# LPC865 register map
Vendor: nxp.com; File version: 1.0
CPU: CM0PLUS r0p0, little endian, no MPU, no FPU, VTOR, 2 interrupt priority bits
Registers are 32-bit, read-write, reset 0x0 unless marked. A register's access mark holds for its fields unless they carry their own. Offsets are from the block's base; [hi:lo] are bit positions; lines under a group give offsets from that group; {n}, {i} and the like mark numbered series; 'fields as' and 'values as' point back to an identical list.

## FTM0 — FTM
Base 0x50009000
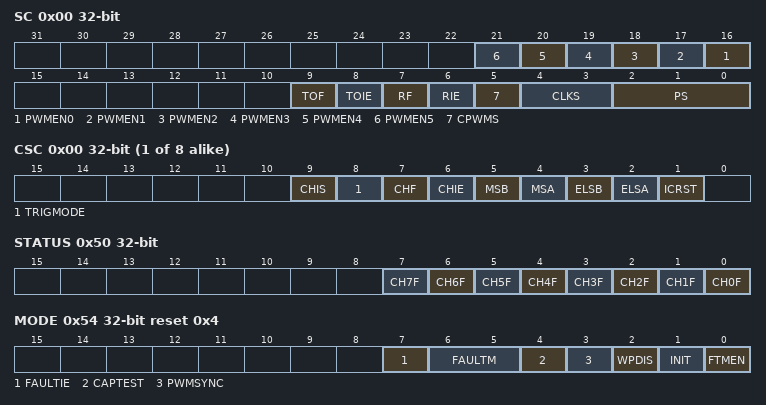
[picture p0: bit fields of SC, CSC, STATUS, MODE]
0x00 SC — Status And Control
  [n+16] PWMEN{n} (n=0..5) — Channel {n} PWM enable bit
    0=PWMEN_disabled (Channel output port is disabled.); 1=PWMEN_enabled (Channel output port is enabled.)
  [9] TOF — Timer Overflow Flag
    0=TOF_nooverflow (FTM counter has not overflowed.); 1=TOF_overflow (FTM counter has overflowed.)
  [8] TOIE — Timer Overflow Interrupt Enable
    0=TOIE_disabletof (Disable TOF interrupts. Use software polling.); 1=TOIE_enabletof (Enable TOF interrupts. An interrupt is generated when TOF equals one.)
  [7] RF — Reload Flag
    0=RF_no (A selected reload point did not happen.); 1=RF_yes (A selected reload point happened.)
  [6] RIE — Reload Point Interrupt Enable
    0=RIE_disabled (Reload point interrupt is disabled.); 1=RIE_enabled (Reload point interrupt is enabled.)
  [5] CPWMS — Center-Aligned PWM Select
    0=CPWMS_upcount (FTM counter operates in Up Counting mode.); 1=CPWMS_updowncount (FTM counter operates in Up-Down Counting mode.)
  [4:3] CLKS — Clock Source Selection
    0=CLKS_noclock (No clock selected. This in effect disables the FTM counter.); 1=CLKS_ftminputclock (FTM input clock); 2=CLKS_ffclk (Fixed frequency clock); 3=CLKS_extclk (External clock)
  [2:0] PS — Prescale Factor Selection
    0=PS_divideby1 (Divide by 1); 1=PS_divideby2 (Divide by 2); 2=PS_divideby4 (Divide by 4); 3=PS_divideby8 (Divide by 8); 4=PS_divideby16 (Divide by 16); 5=PS_divideby32 (Divide by 32); 6=PS_divideby64 (Divide by 64); 7=PS_divideby128 (Divide by 128)
0x04 CNT — Counter
  [15:0] COUNT — Counter Value
0x08 MOD — Modulo
  [15:0] MOD
{0xC+8i} CONTROLS[{i}] (i=0..7) group
  0x00 CSC — Channel (n) Status And Control
    [9] CHIS ro — Channel (n) Input State
      0=CHIS_zero (The channel (n) input is zero.); 1=CHIS_one (The channel (n) input is one.)
    [8] TRIGMODE — Trigger mode control
      0=TRIGMODE_normal (Channel outputs will generate the normal PWM outputs without generating a pulse.); 1=TRIGMODE_trigger (If a match in the channel occurs, a trigger generation on channel output will happen. The trigger pulse width has one FTM clock cycle.)
    [7] CHF — Channel (n) Flag
      0=CHF_event_no (No channel (n) event has occurred.); 1=CHF_event_yes (A channel (n) event has occurred.)
    [6] CHIE — Channel (n) Interrupt Enable
      0=CHIE_disable (Disable channel (n) interrupt. Use software polling.); 1=CHIE_enable (Enable channel (n) interrupt.)
    [5] MSB — Channel (n) Mode Select
    [4] MSA — Channel (n) Mode Select
    [3] ELSB — Channel (n) Edge or Level Select
    [2] ELSA — Channel (n) Edge or Level Select
    [1] ICRST — FTM counter reset by the selected input capture event.
      0=ICRST_notreset (FTM counter is not reset when the selected channel (n) input event is detected.); 1=ICRST_reset (FTM counter is reset when the selected channel (n) input event is detected.)
  0x04 CV — Channel (n) Value
    [15:0] VAL — Channel Value
0x4C CNTIN — Counter Initial Value
  [15:0] INIT
0x50 STATUS — Capture And Compare Status
  [all] fields
    0=CHF_event_no (No channel event has occurred.); 1=CHF_event_yes (A channel event has occurred.)
  [n] CH{n}F (n=0..7) — Channel {n} Flag
0x54 MODE reset 0x4 — Features Mode Selection
  [7] FAULTIE — Fault Interrupt Enable
    0=FAULTIE_disabled (Fault control interrupt is disabled.); 1=FAULTIE_enabled (Fault control interrupt is enabled.)
  [6:5] FAULTM — Fault Control Mode
    0=FAULTM_disabled (Fault control is disabled for all channels.); 1=FAULTM_enabled_even (Fault control is enabled for even channels only (channels 0, 2, 4, and 6), and the selected mode is the manual fault clearing.); 2=FAULTM_enabled_manual (Fault control is enabled for all channels, and the selected mode is the manual fault clearing.); 3=FAULTM_enabled_auto (Fault control is enabled for all channels, and the selected mode is the automatic fault clearing.)
  [4] CAPTEST — Capture Test Mode Enable
    0=CAPTEST_disabled (Capture test mode is disabled.); 1=CAPTEST_enabled (Capture test mode is enabled.)
  [3] PWMSYNC — PWM Synchronization Mode
    0=PWMSYNC_restrict_no (No restrictions. Software and hardware triggers can be used by MOD, CnV, OUTMASK, and FTM counter synchronization.); 1=PWMSYNC_restrict_yes (Software trigger can only be used by MOD and CnV synchronization, and hardware triggers can only be used by OUTMASK and FTM counter synchronization.)
  [2] WPDIS — Write Protection Disable
    0=WPDIS_enabled (Write protection is enabled.); 1=WPDIS_disabled (Write protection is disabled.)
  [1] INIT — Initialize The Channels Output
  [0] FTMEN — FTM Enable
    0=FTMEN_compatible_yes (TPM compatibility. Free running counter and synchronization compatible with TPM.); 1=FTMEN_compatible_no (Free running counter and synchronization are different from TPM behavior.)
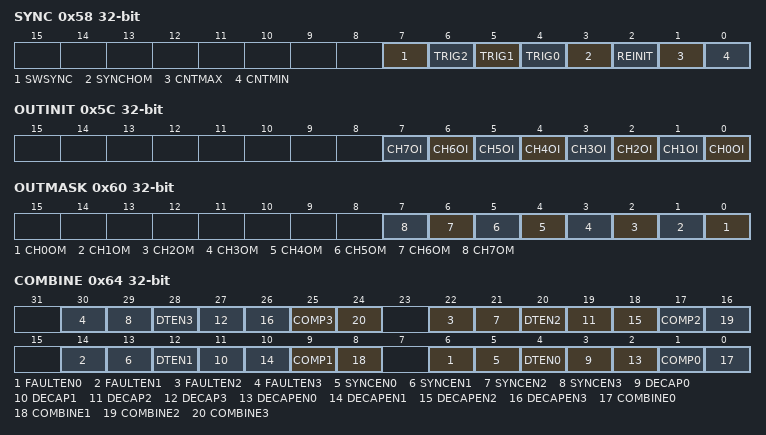
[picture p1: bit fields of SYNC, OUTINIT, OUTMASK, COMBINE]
0x58 SYNC — Synchronization
  [7] SWSYNC — PWM Synchronization Software Trigger
    0=SWSYNC_notselected (Software trigger is not selected.); 1=SWSYNC_selected (Software trigger is selected.)
  [6] TRIG2 — PWM Synchronization Hardware Trigger 2
    0=TRIG2_disabled (Trigger is disabled.); 1=TRIG2_enabled (Trigger is enabled.)
  [5] TRIG1 — PWM Synchronization Hardware Trigger 1
    0=TRIG1_disabled (Trigger is disabled.); 1=TRIG1_enabled (Trigger is enabled.)
  [4] TRIG0 — PWM Synchronization Hardware Trigger 0
    0=TRIG0_disabled (Trigger is disabled.); 1=TRIG0_enabled (Trigger is enabled.)
  [3] SYNCHOM — Output Mask Synchronization
    0=SYNCHOM_ftm (OUTMASK register is updated with the value of its buffer in all rising edges of the FTM input clock.); 1=SYNCHOM_pwm (OUTMASK register is updated with the value of its buffer only by the PWM synchronization.)
  [2] REINIT — FTM Counter Reinitialization by Synchronization
    0=REINIT_normal (FTM counter continues to count normally.); 1=REINIT_trigger (FTM counter is updated with its initial value when the selected trigger is detected.)
  [1] CNTMAX — Maximum Loading Point Enable
    0=CNTMAX_disabled (The maximum loading point is disabled.); 1=CNTMAX_enabled (The maximum loading point is enabled.)
  [0] CNTMIN — Minimum Loading Point Enable
    0=CNTMIN_disabled (The minimum loading point is disabled.); 1=CNTMIN_enabled (The minimum loading point is enabled.)
0x5C OUTINIT — Initial State For Channels Output
  [all] fields
    0=CHOI_zero (The initialization value is 0.); 1=CHOI_one (The initialization value is 1.)
  [n] CH{n}OI (n=0..7) — Channel {n} Output Initialization Value
0x60 OUTMASK — Output Mask
  [all] fields
    0=CHOM_normal (Channel output is not masked. It continues to operate normally.); 1=CHOM_inactive (Channel output is masked. It is forced to its inactive state.)
  [n] CH{n}OM (n=0..7) — Channel {n} Output Mask
0x64 COMBINE — Function For Linked Channels
  [8n+6] FAULTEN{n} (n=0..3) — Fault Control Enable For n = {2n}
    0=FAULTEN{n}_disabled (The fault control in this pair of channels is disabled.); 1=FAULTEN{n}_enabled (The fault control in this pair of channels is enabled.)
  [8n+5] SYNCEN{n} (n=0..3) — Synchronization Enable For n = {2n}
    0=SYNCEN{n}_disabled (The PWM synchronization in this pair of channels is disabled.); 1=SYNCEN{n}_enabled (The PWM synchronization in this pair of channels is enabled.)
  [8n+4] DTEN{n} (n=0..3) — Deadtime Enable For n = {2n}
    0=DTEN{n}_disabled (The deadtime insertion in this pair of channels is disabled.); 1=DTEN{n}_enabled (The deadtime insertion in this pair of channels is enabled.)
  [8n+3] DECAP{n} (n=0..3) — Dual Edge Capture Mode Captures For n = {2n}
    0=DECAP{n}_inactive (The dual edge captures are inactive.); 1=DECAP{n}_active (The dual edge captures are active.)
  [8n+2] DECAPEN{n} (n=0..3) — Dual Edge Capture Mode Enable For n = {2n}
  [25] COMP3 — Complement Of Channel (n) for n = 6
    0=COMP3_same_modcomb (If the channels (n) and (n+1) are in Combine Mode or Modified Combine PWM Mode, the channel (n+1) output is the same as the channel (n) output. If the channel (n+1) is in Output Compare Mode, EPWM or CPWM, the channel (n+1) output is independent from channel (n) output.); 1=COMP3_complement (The channel (n+1) output is the complement of the channel (n) output.)
  [8n] COMBINE{n} (n=0..3) — Combine Channels For n = {2n}
  [17] COMP2 — Complement Of Channel (n) For n = 4
    0=COMP2_same_modcomb (If the channels (n) and (n+1) are in Combine Mode or Modified Combine PWM Mode, the channel (n+1) output is the same as the channel (n) output. If the channel (n+1) is in Output Compare Mode, EPWM or CPWM, the channel (n+1) output is independent from channel (n) output.); 1=COMP2_complement (The channel (n+1) output is the complement of the channel (n) output.)
  [9] COMP1 — Complement Of Channel (n) For n = 2
    0=COMP1_modcomb (If the channels (n) and (n+1) are in Combine Mode or Modified Combine PWM Mode, the channel (n+1) output is the same as the channel (n) output. If the channel (n+1) is in Output Compare Mode, EPWM or CPWM, the channel (n+1) output is independent from channel (n) output.); 1=COMP1_complement (The channel (n+1) output is the complement of the channel (n) output.)
  [1] COMP0 — Complement Of Channel (n) For n = 0
    0=COMP0_same_modcomb (If the channels (n) and (n+1) are in Combine Mode or Modified Combine PWM Mode, the channel (n+1) output is the same as the channel (n) output. If the channel (n+1) is in Output Compare Mode, EPWM or CPWM, the channel (n+1) output is independent from channel (n) output.); 1=COMP0_complement (The channel (n+1) output is the complement of the channel (n) output.)
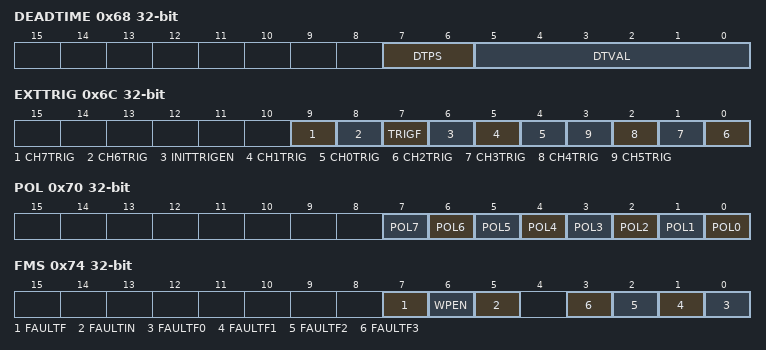
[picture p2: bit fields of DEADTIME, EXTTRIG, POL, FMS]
0x68 DEADTIME — Deadtime Configuration
  [7:6] DTPS — Deadtime Prescaler Value
    0b0x=DTPS_divideby1 (Divide the FTM input clock by 1.); 2=DTPS_divideby4 (Divide the FTM input clock by 4.); 3=DTPS_divideby16 (Divide the FTM input clock by 16.)
  [5:0] DTVAL — Deadtime Value
0x6C EXTTRIG — FTM External Trigger
  [9] CH7TRIG — Channel 7 External Trigger Enable
    0=CH7TRIG_disabled (The generation of this external trigger is disabled.); 1=CH7TRIG_enabled (The generation of this external trigger is enabled.)
  [8] CH6TRIG — Channel 6 External Trigger Enable
    0=CH6TRIG_disabled (The generation of this external trigger is disabled.); 1=CH6TRIG_enabled (The generation of this external trigger is enabled.)
  [7] TRIGF — Channel Trigger Flag
    0=TRIGF_no (No channel trigger was generated.); 1=TRIGF_yes (A channel trigger was generated.)
  [6] INITTRIGEN — Initialization Trigger Enable
    0=INITTRIGEN_disabled (The generation of initialization trigger is disabled.); 1=INITTRIGEN_enabled (The generation of initialization trigger is enabled.)
  [5] CH1TRIG — Channel 1 External Trigger Enable
    0=CH1TRIG_disabled (The generation of this external trigger is disabled.); 1=CH1TRIG_enabled (The generation of this external trigger is enabled.)
  [4] CH0TRIG — Channel 0 External Trigger Enable
    0=CH0TRIG_disabled (The generation of this external trigger is disabled.); 1=CH0TRIG_enabled (The generation of this external trigger is enabled.)
  [n-2] CH{n}TRIG (n=2..5) — Channel {n} External Trigger Enable
    0=CH{n}TRIG_disabled (The generation of this external trigger is disabled.); 1=CH{n}TRIG_enabled (The generation of this external trigger is enabled.)
0x70 POL — Channels Polarity
  [all] fields
    0=POL_high (The channel polarity is active high.); 1=POL_low (The channel polarity is active low.)
  [n] POL{n} (n=0..7) — Channel {n} Polarity
0x74 FMS — Fault Mode Status
  [7] FAULTF — Fault Detection Flag
    0=FAULTF_no (No fault condition was detected.); 1=FAULTF_yes (A fault condition was detected.)
  [6] WPEN — Write Protection Enable
    0=WPEN_disabled (Write protection is disabled. Write protected bits can be written.); 1=WPEN_enabled (Write protection is enabled. Write protected bits cannot be written.)
  [5] FAULTIN ro — Fault Inputs
    0=FAULTIN_zero (The logic OR of the enabled fault inputs is 0.); 1=FAULTIN_one (The logic OR of the enabled fault inputs is 1.)
  [n] FAULTF{n} (n=0..3) — Fault Detection Flag {n}
    0=FAULTF{n}_no (No fault condition was detected at the fault input.); 1=FAULTF{n}_yes (A fault condition was detected at the fault input.)
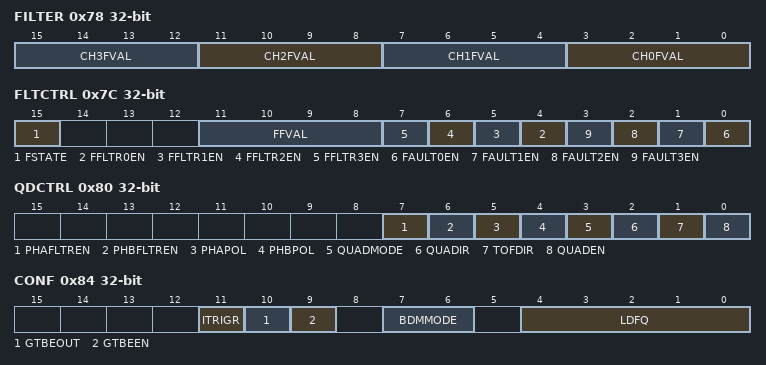
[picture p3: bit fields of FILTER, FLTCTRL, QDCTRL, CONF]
0x78 FILTER — Input Capture Filter Control
  [4n+3:4n] CH{n}FVAL (n=0..3) — Channel {n} Input Filter
0x7C FLTCTRL — Fault Control
  [15] FSTATE — Fault output state
    0=FSTATE_safe (FTM outputs will be placed into safe values when fault events in ongoing (defined by POL bits).); 1=FSTATE_tristate (FTM outputs will be tri-stated when fault event is ongoing)
  [11:8] FFVAL — Fault Input Filter
  [n+4] FFLTR{n}EN (n=0..3) — Fault Input {n} Filter Enable
    0=FFLTR{n}EN_disabled (Fault input filter is disabled.); 1=FFLTR{n}EN_enabled (Fault input filter is enabled.)
  [n] FAULT{n}EN (n=0..3) — Fault Input {n} Enable
    0=FAULT{n}EN_disabled (Fault input is disabled.); 1=FAULT{n}EN_enabled (Fault input is enabled.)
0x80 QDCTRL — Quadrature Decoder Control And Status
  [7] PHAFLTREN — Phase A Input Filter Enable
    0=PHAFLTREN_disabled (Phase A input filter is disabled.); 1=PHAFLTREN_enabled (Phase A input filter is enabled.)
  [6] PHBFLTREN — Phase B Input Filter Enable
    0=PHBFLTREN_disabled (Phase B input filter is disabled.); 1=PHBFLTREN_enabled (Phase B input filter is enabled.)
  [5] PHAPOL — Phase A Input Polarity
    0=PHAPOL_normal (Normal polarity. Phase A input signal is not inverted before identifying the rising and falling edges of this signal.); 1=PHAPOL_inverted (Inverted polarity. Phase A input signal is inverted before identifying the rising and falling edges of this signal.)
  [4] PHBPOL — Phase B Input Polarity
    0=PHBPOL_normal (Normal polarity. Phase B input signal is not inverted before identifying the rising and falling edges of this signal.); 1=PHBPOL_inverted (Inverted polarity. Phase B input signal is inverted before identifying the rising and falling edges of this signal.)
  [3] QUADMODE — Quadrature Decoder Mode
    0=QUADMODE_aandb (Phase A and phase B encoding mode.); 1=QUADMODE_candd (Count and direction encoding mode.)
  [2] QUADIR ro — FTM Counter Direction In Quadrature Decoder Mode
    0=QUADIR_decrement (Counting direction is decreasing (FTM counter decrement).); 1=QUADIR_increment (Counting direction is increasing (FTM counter increment).)
  [1] TOFDIR ro — Timer Overflow Direction In Quadrature Decoder Mode
    0=TOFDIR_bottom (TOF bit was set on the bottom of counting. There was an FTM counter decrement and FTM counter changes from its minimum value (CNTIN register) to its maximum value (MOD register).); 1=TOFDIR_top (TOF bit was set on the top of counting. There was an FTM counter increment and FTM counter changes from its maximum value (MOD register) to its minimum value (CNTIN register).)
  [0] QUADEN — Quadrature Decoder Mode Enable
    0=QUADEN_disabled (Quadrature Decoder mode is disabled.); 1=QUADEN_enabled (Quadrature Decoder mode is enabled.)
0x84 CONF — Configuration
  [11] ITRIGR — Initialization trigger on Reload Point
    0=ITRIGR_counter (Initialization trigger is generated on counter wrap events.); 1=ITRIGR_reload (Initialization trigger is generated when a reload point is reached.)
  [10] GTBEOUT — Global Time Base Output
    0=GTBEOUT_disabled (A global time base signal generation is disabled.); 1=GTBEOUT_enabled (A global time base signal generation is enabled.)
  [9] GTBEEN — Global Time Base Enable
    0=GTBEEN_disabled (Use of an external global time base is disabled.); 1=GTBEEN_enabled (Use of an external global time base is enabled.)
  [7:6] BDMMODE — Debug Mode
  [4:0] LDFQ — Frequency of the Reload Opportunities
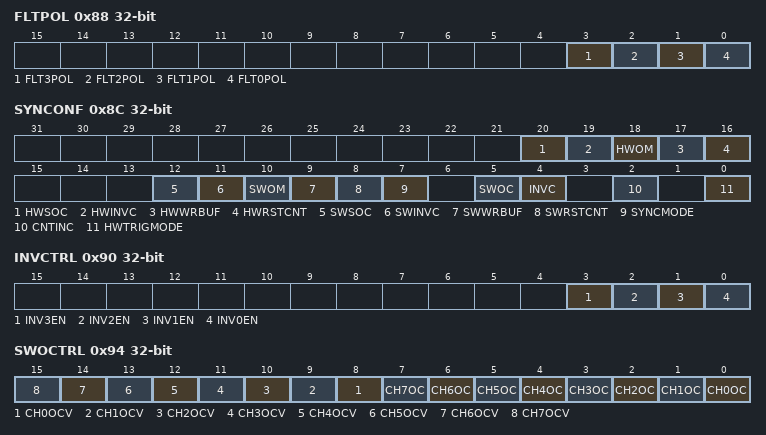
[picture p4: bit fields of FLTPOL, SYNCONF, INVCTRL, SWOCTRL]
0x88 FLTPOL — FTM Fault Input Polarity
  [3] FLT3POL — Fault Input 3 Polarity
    0=FLT3POL_high (The fault input polarity is active high. A 1 at the fault input indicates a fault.); 1=FLT2POL_low (The fault input polarity is active low. A 0 at the fault input indicates a fault.)
  [2] FLT2POL — Fault Input 2 Polarity
    0=FLT2POL_high (The fault input polarity is active high. A 1 at the fault input indicates a fault.); 1=FLT2POL_low (The fault input polarity is active low. A 0 at the fault input indicates a fault.)
  [1] FLT1POL — Fault Input 1 Polarity
    0=FLT1POL_high (The fault input polarity is active high. A 1 at the fault input indicates a fault.); 1=FLT1POL_low (The fault input polarity is active low. A 0 at the fault input indicates a fault.)
  [0] FLT0POL — Fault Input 0 Polarity
    0=FLT0POL_high (The fault input polarity is active high. A 1 at the fault input indicates a fault.); 1=FLT0POL_low (The fault input polarity is active low. A 0 at the fault input indicates a fault.)
0x8C SYNCONF — Synchronization Configuration
  [20] HWSOC — Software output control synchronization is activated by a hardware trigger
    0=HWSOC_inactive (A hardware trigger does not activate the SWOCTRL register synchronization.); 1=HWSOC_active (A hardware trigger activates the SWOCTRL register synchronization.)
  [19] HWINVC — Inverting control synchronization is activated by a hardware trigger
    0=HWINVC_inactive (A hardware trigger does not activate the INVCTRL register synchronization.); 1=HWINVC_active (A hardware trigger activates the INVCTRL register synchronization.)
  [18] HWOM — Output mask synchronization is activated by a hardware trigger
    0=HWOM_inactive (A hardware trigger does not activate the OUTMASK register synchronization.); 1=HWOM_active (A hardware trigger activates the OUTMASK register synchronization.)
  [17] HWWRBUF — MOD, HCR, CNTIN, and CV registers synchronization is activated by a hardware trigger
    0=HWWRBUF_inactive (A hardware trigger does not activate MOD, HCR, CNTIN, and CV registers synchronization.); 1=HWWRBUF_active (A hardware trigger activates MOD, HCR, CNTIN, and CV registers synchronization.)
  [16] HWRSTCNT — FTM counter synchronization is activated by a hardware trigger
    0=HWRSTCNT_inactive (A hardware trigger does not activate the FTM counter synchronization.); 1=HWRSTCNT_active (A hardware trigger activates the FTM counter synchronization.)
  [12] SWSOC — Software output control synchronization is activated by the software trigger
    0=SWSOC_inactive (The software trigger does not activate the SWOCTRL register synchronization.); 1=SWSOC_active (The software trigger activates the SWOCTRL register synchronization.)
  [11] SWINVC — Inverting control synchronization is activated by the software trigger
    0=SWINVC_inactive (The software trigger does not activate the INVCTRL register synchronization.); 1=SWINVC_active (The software trigger activates the INVCTRL register synchronization.)
  [10] SWOM — Output mask synchronization is activated by the software trigger
    0=SWOM_inactive (The software trigger does not activate the OUTMASK register synchronization.); 1=SWOM_active (The software trigger activates the OUTMASK register synchronization.)
  [9] SWWRBUF — MOD, HCR, CNTIN, and CV registers synchronization is activated by the software trigger
    0=SWWRBUF_inactive (The software trigger does not activate MOD, HCR, CNTIN, and CV registers synchronization.); 1=SWWRBUF_active (The software trigger activates MOD, HCR, CNTIN, and CV registers synchronization.)
  [8] SWRSTCNT — FTM counter synchronization is activated by the software trigger
    0=SWRSTCNT_inactive (The software trigger does not activate the FTM counter synchronization.); 1=SWRSTCNT_active (The software trigger activates the FTM counter synchronization.)
  [7] SYNCMODE — Synchronization Mode
    0=SYNCMODE_legacy (Legacy PWM synchronization is selected.); 1=SYNCMODE_enhanced (Enhanced PWM synchronization is selected.)
  [5] SWOC — SWOCTRL Register Synchronization
    0=SWOC_input (SWOCTRL register is updated with its buffer value at all rising edges of FTM input clock.); 1=SWOC_pwm (SWOCTRL register is updated with its buffer value by the PWM synchronization.)
  [4] INVC — INVCTRL Register Synchronization
    0=INVC_input (INVCTRL register is updated with its buffer value at all rising edges of FTM input clock.); 1=INVC_pwm (INVCTRL register is updated with its buffer value by the PWM synchronization.)
  [2] CNTINC — CNTIN Register Synchronization
    0=CNTINC_input (CNTIN register is updated with its buffer value at all rising edges of FTM input clock.); 1=CNTINC_pwm (CNTIN register is updated with its buffer value by the PWM synchronization.)
  [0] HWTRIGMODE — Hardware Trigger Mode
    0=HWTRIGMODE_clears_yes (FTM clears the TRIGj bit when the hardware trigger j is detected, where j = 0, 1,2.); 1=HWTRIGMODE_clears_no (FTM does not clear the TRIGj bit when the hardware trigger j is detected, where j = 0, 1,2.)
0x90 INVCTRL — FTM Inverting Control
  [3] INV3EN — Pair Channels 3 Inverting Enable
    0=INV2EN_disabled (Inverting is disabled.); 1=INV2EN_enabled (Inverting is enabled.)
  [2] INV2EN — Pair Channels 2 Inverting Enable
    values as INV3EN
  [1] INV1EN — Pair Channels 1 Inverting Enable
    0=INV1EN_disabled (Inverting is disabled.); 1=INV1EN_enabled (Inverting is enabled.)
  [0] INV0EN — Pair Channels 0 Inverting Enable
    0=INV0EN_disabled (Inverting is disabled.); 1=INV0EN_enabled (Inverting is enabled.)
0x94 SWOCTRL — FTM Software Output Control
  [n+8] CH{n}OCV (n=0..7) — Channel {n} Software Output Control Value
    0=CHOCV_zero (The software output control forces 0 to the channel output.); 1=CHOCV_one (The software output control forces 1 to the channel output.)
  [n] CH{n}OC (n=0..7) — Channel {n} Software Output Control Enable
    0=CHOC_not_affected (The channel output is not affected by software output control.); 1=CHOC_affected (The channel output is affected by software output control.)
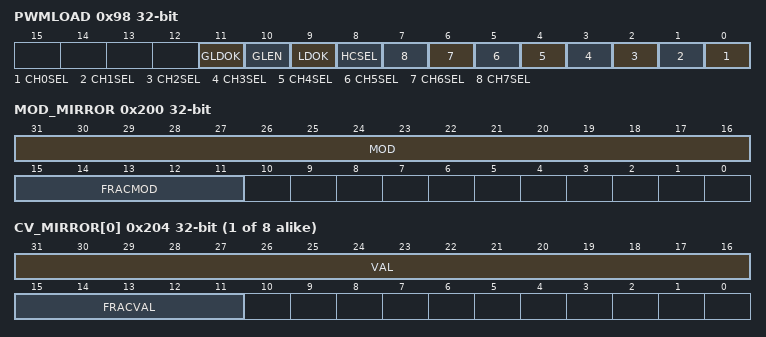
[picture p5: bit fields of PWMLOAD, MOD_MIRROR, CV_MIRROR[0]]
0x98 PWMLOAD — FTM PWM Load
  [11] GLDOK — Global Load OK
    0=GLDOK_no (No action.); 1=GLDOK_yes (LDOK bit is set.)
  [10] GLEN — Global Load Enable
    0=GLEN_disabled (Global Load Ok disabled.); 1=GLEN_enabled (Global Load OK enabled. A pulse event on the module global load input sets the LDOK bit.)
  [9] LDOK — Load Enable
    0=LDOK_disabled (Loading updated values is disabled.); 1=LDOK_enabled (Loading updated values is enabled.)
  [8] HCSEL — Half Cycle Select
    0=HCSEL_disabled (Half cycle reload is disabled and it is not considered as a reload opportunity.); 1=HCSEL_enabled (Half cycle reload is enabled and it is considered as a reload opportunity.)
  [n] CH{n}SEL (n=0..7) — Channel {n} Select
    0=CHSEL_reload_no (Channel match is not included as a reload opportunity.); 1=CHSEL_reload_yes (Channel match is included as a reload opportunity.)
0x9C HCR — Half Cycle Register
  [15:0] HCVAL — Half Cycle Value
0x200 MOD_MIRROR — Mirror of Modulo Value
  [31:16] MOD — Mirror of the Modulo Integer Value
  [15:11] FRACMOD — Modulo Fractional Value
{0x204+4i} CV_MIRROR[{i}] (i=0..7) — Mirror of Channel (n) Match Value
  [31:16] VAL — Mirror of the Channel (n) Match Integer Value
  [15:11] FRACVAL — Channel (n) Match Fractional Value
